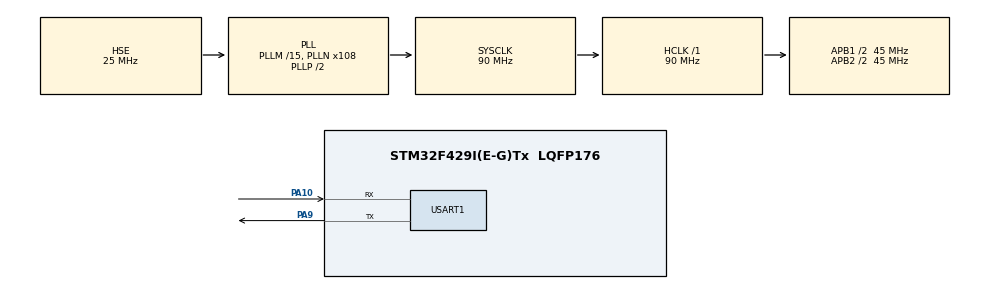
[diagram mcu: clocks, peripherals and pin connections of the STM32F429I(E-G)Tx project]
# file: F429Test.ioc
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Dma.Request0=USART1_TX
Dma.USART1_TX.0.Direction=DMA_MEMORY_TO_PERIPH
Dma.USART1_TX.0.FIFOMode=DMA_FIFOMODE_DISABLE
Dma.USART1_TX.0.Instance=DMA2_Stream7
Dma.USART1_TX.0.MemDataAlignment=DMA_MDATAALIGN_BYTE
Dma.USART1_TX.0.MemInc=DMA_MINC_ENABLE
Dma.USART1_TX.0.Mode=DMA_NORMAL
Dma.USART1_TX.0.PeriphDataAlignment=DMA_PDATAALIGN_BYTE
Dma.USART1_TX.0.PeriphInc=DMA_PINC_DISABLE
Dma.USART1_TX.0.Priority=DMA_PRIORITY_LOW
Mcu.Family=STM32F4
Mcu.Name=STM32F429I(E-G)Tx
Mcu.Package=LQFP176
NVIC.DMA2_Stream7_IRQn=true\:0\:0\:false\:false\:true\:false\:true
NVIC.PriorityGroup=NVIC_PRIORITYGROUP_4
NVIC.RCC_IRQn=true\:0\:0\:false\:false\:true\:true\:false
NVIC.TIM2_IRQn=true\:0\:0\:false\:false\:true\:true\:true
NVIC.USART1_IRQn=true\:0\:0\:false\:false\:true\:true\:true
PA10.Mode=Asynchronous
PA10.Signal=USART1_RX
PA13.Mode=Serial_Wire
PA13.Signal=SYS_JTMS-SWDIO
PA14.Mode=Serial_Wire
PA14.Signal=SYS_JTCK-SWCLK
PA9.Mode=Asynchronous
PA9.Signal=USART1_TX
PC14/OSC32_IN.Mode=LSE-External-Oscillator
PC14/OSC32_IN.Signal=RCC_OSC32_IN
PC15/OSC32_OUT.Mode=LSE-External-Oscillator
PC15/OSC32_OUT.Signal=RCC_OSC32_OUT
PH0/OSC_IN.Mode=HSE-External-Oscillator
PH0/OSC_IN.Signal=RCC_OSC_IN
PH1/OSC_OUT.Mode=HSE-External-Oscillator
PH1/OSC_OUT.Signal=RCC_OSC_OUT
ProjectManager.HeapSize=0x200
ProjectManager.StackSize=0x400
ProjectManager.TargetToolchain=MDK-ARM V5
RCC.48MHZClocksFreq_Value=45000000
RCC.AHBFreq_Value=90000000
RCC.APB1CLKDivider=RCC_HCLK_DIV2
RCC.APB1Freq_Value=45000000
RCC.APB1TimFreq_Value=90000000
RCC.APB2CLKDivider=RCC_HCLK_DIV2
RCC.APB2Freq_Value=45000000
RCC.APB2TimFreq_Value=90000000
RCC.CortexFreq_Value=90000000
RCC.HCLKFreq_Value=90000000
RCC.HSE_VALUE=25000000
RCC.HSI_VALUE=16000000
RCC.PLLM=15
RCC.PLLN=108
RCC.PLLSourceVirtual=RCC_PLLSOURCE_HSE
RCC.RCC_RTC_Clock_Source=RCC_RTCCLKSOURCE_LSE
RCC.RCC_RTC_Clock_SourceVirtual=RCC_RTCCLKSOURCE_LSE
RCC.SYSCLKFreq_VALUE=90000000
RCC.SYSCLKSource=RCC_SYSCLKSOURCE_PLLCLK
RCC.VCOOutputFreq_Value=180000000
TIM2.Period=999
TIM2.Prescaler=89
USART1.VirtualMode=VM_ASYNC
VP_TIM2_VS_ClockSourceINT.Mode=Internal
board=custom

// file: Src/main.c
/* USER CODE BEGIN Header */
/**
  ******************************************************************************
  * @file           : main.c
  * @brief          : Main program body
  ******************************************************************************
  * @attention
  *
  * <h2><center>&copy; Copyright (c) 2019 STMicroelectronics.
  * All rights reserved.</center></h2>
  *
  * This software component is licensed by ST under BSD 3-Clause license,
  * the "License"; You may not use this file except in compliance with the
  * License. You may obtain a copy of the License at:
  *                        opensource.org/licenses/BSD-3-Clause
  *
  ******************************************************************************
  */
/* USER CODE END Header */

#include "main.h"
#include "dma.h"
#include "tim.h"
#include "usart.h"
#include "gpio.h"

/* USER CODE BEGIN PV */
uint32_t TestCycle;
uint8_t  TestCycleFlag;
/* USER CODE END PV */

void SystemClock_Config(void);

/* USER CODE BEGIN 0 */
uint8_t add;
uint8_t str[4] = {0x01,0x02,0x03,0x04};

struct information{
	uint8_t age;
	uint8_t record;
	struct  information* next;
};

/* USER CODE END 0 */

int main(void)
{

  /* MCU Configuration--------------------------------------------------------*/

  /* Reset of all peripherals, Initializes the Flash interface and the Systick. */
  HAL_Init();

  /* Configure the system clock */
  SystemClock_Config();

  /* Initialize all configured peripherals */
  MX_GPIO_Init();
  MX_DMA_Init();
  MX_TIM2_Init();
  MX_USART1_UART_Init();
  /* USER CODE BEGIN 2 */
	HAL_TIM_Base_Start_IT(&htim2);

  /* USER CODE END 2 */

  /* Infinite loop */
  /* USER CODE BEGIN WHILE */
  while (1)
  {
//		if(TestCycleFlag == 1)
//		{
//			TestCycleFlag = 0;
//			HAL_UART_Transmit_DMA(&huart1,str,4);
//		}
		add = 254;
		add = add + 1;

    /* USER CODE END WHILE */

  }
}

void SystemClock_Config(void)
{
  RCC_OscInitTypeDef RCC_OscInitStruct = {0};
  RCC_ClkInitTypeDef RCC_ClkInitStruct = {0};

  /** Configure the main internal regulator output voltage
  */
  __HAL_RCC_PWR_CLK_ENABLE();
  __HAL_PWR_VOLTAGESCALING_CONFIG(PWR_REGULATOR_VOLTAGE_SCALE3);
  /** Initializes the CPU, AHB and APB busses clocks
  */
  RCC_OscInitStruct.OscillatorType = RCC_OSCILLATORTYPE_HSE;
  RCC_OscInitStruct.HSEState = RCC_HSE_ON;
  RCC_OscInitStruct.PLL.PLLState = RCC_PLL_ON;
  RCC_OscInitStruct.PLL.PLLSource = RCC_PLLSOURCE_HSE;
  RCC_OscInitStruct.PLL.PLLM = 15;
  RCC_OscInitStruct.PLL.PLLN = 108;
  RCC_OscInitStruct.PLL.PLLP = RCC_PLLP_DIV2;
  RCC_OscInitStruct.PLL.PLLQ = 4;
  if (HAL_RCC_OscConfig(&RCC_OscInitStruct) != HAL_OK)
  {
    Error_Handler();
  }
  /** Activate the Over-Drive mode
  */
  if (HAL_PWREx_EnableOverDrive() != HAL_OK)
  {
    Error_Handler();
  }
  /** Initializes the CPU, AHB and APB busses clocks
  */
  RCC_ClkInitStruct.ClockType = RCC_CLOCKTYPE_HCLK|RCC_CLOCKTYPE_SYSCLK
                              |RCC_CLOCKTYPE_PCLK1|RCC_CLOCKTYPE_PCLK2;
  RCC_ClkInitStruct.SYSCLKSource = RCC_SYSCLKSOURCE_PLLCLK;
  RCC_ClkInitStruct.AHBCLKDivider = RCC_SYSCLK_DIV1;
  RCC_ClkInitStruct.APB1CLKDivider = RCC_HCLK_DIV2;
  RCC_ClkInitStruct.APB2CLKDivider = RCC_HCLK_DIV2;

  if (HAL_RCC_ClockConfig(&RCC_ClkInitStruct, FLASH_LATENCY_2) != HAL_OK)
  {
    Error_Handler();
  }
}

/* USER CODE BEGIN 4 */
void HAL_TIM_PeriodElapsedCallback(TIM_HandleTypeDef *htim)
{
	if(htim->Instance == TIM2)	//1ms
	{
		TestCycle++;
		//定时500ms
    if(TestCycle % 500 == 0) TestCycleFlag = 1;
	}
}

/* USER CODE END 4 */

void Error_Handler(void)
{
}

/************************ (C) COPYRIGHT STMicroelectronics *****END OF FILE****/
